# STM32L4Q5xx register map
File version: 1.0
Registers are 32-bit, read-write, reset 0x0 unless marked. A register's access mark holds for its fields unless they carry their own. Offsets are from the block's base; [hi:lo] are bit positions; {n}, {i} and the like mark numbered series.

## PWR — Power Control
Base 0x40007000
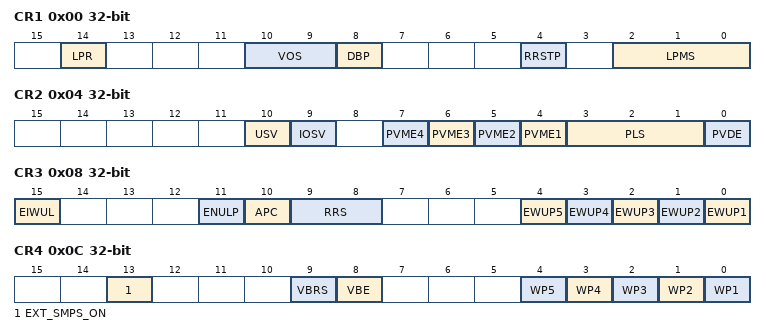
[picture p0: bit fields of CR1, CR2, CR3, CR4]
0x00 CR1 — PWR power control register 1
  [14] LPR — Regulator low-power mode
  [10:9] VOS — VOS[1:0] bits (Regulator voltage scaling output selection)
    1=SCALE1; 2=SCALE2
  [8] DBP — Disable Back-up domain Protection
  [4] RRSTP — SRAM3 Retention in Stop 2 mode
  [2:0] LPMS — Low-power mode selection field
    0=STOP0; 1=STOP1; 2=STOP2; 3=STANDBY; 4=SHUTDOWN
0x04 CR2 — PWR power control register 2
  [10] USV — VDD USB Supply Valid
  [9] IOSV — VDD IO2 independent I/Os Supply Valid
  [n+3] PVME{n} (n=1..4) — PVM {n} Enable
  [3:1] PLS — PVD level selection
    {v}=PVDLEVEL_{v} (v=0..7)
  [0] PVDE — Power Voltage Detector Enable
0x08 CR3 — PWR power control register 3
  [15] EIWUL — Enable Internal Wake-up line
  [11] ENULP — Enable ULP BORL, BORH and PVD for STOP2 and Standby modes
  [10] APC — Apply pull-up and pull-down configuration
  [9:8] RRS
    0=NO_SRAM2_RETENTION; 1=FULL_SRAM2_RETENTION; 2=PWR_4KBYTES_SRAM2_RETENTION
  [n-1] EWUP{n} (n=1..5) — Enable Wake-Up Pin {n}
0x0C CR4 — PWR power control register 4
  [13] EXT_SMPS_ON — Inform the internal regulator on external SMPS switch status
  [9] VBRS — VBAT Battery charging Resistor Selection
    0=CHARG_RESISTOR_5K; 1=CHARGRESISTOR_1_5K
  [8] VBE — VBAT Battery charging Enable
  [n-1] WP{n} (n=1..5) — Wake-Up Pin {n} polarity
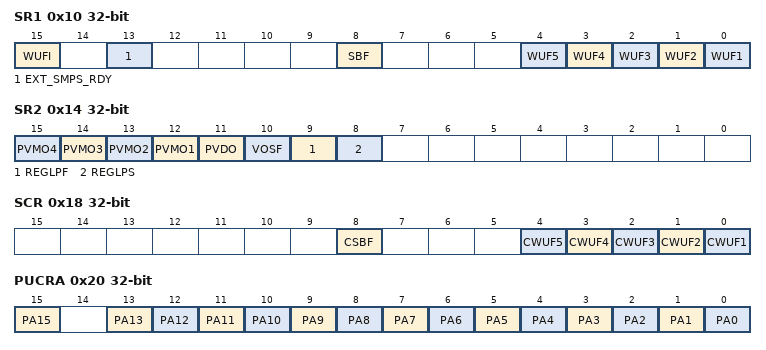
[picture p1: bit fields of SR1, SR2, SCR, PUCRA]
0x10 SR1 — PWR power status register 1
  [15] WUFI — Wake-Up Flag Internal
  [13] EXT_SMPS_RDY — Switching to external SMPS Ready Flag
  [8] SBF — Stand-By Flag
  [n-1] WUF{n} (n=1..5) — Wake-up Flag {n}
0x14 SR2 — PWR power status register 2
  [n+11] PVMO{n} (n=1..4) — Peripheral Voltage Monitoring Output {n}
  [11] PVDO — Power Voltage Detector Output
  [10] VOSF — Voltage Scaling Flag
  [9] REGLPF — Low-power Regulator Flag
  [8] REGLPS — Low-power Regulator Started
0x18 SCR — PWR power status reset register
  [8] CSBF — Clear Stand-By Flag
  [n-1] CWUF{n} (n=1..5) — Clear Wake-up Flag {n}
0x20 PUCRA — Pull_up control register of portA
  [15] PA15 — Port PA15 Pull-Up set
  [n] PA{n} (n=0..13) — Port PA{n} Pull-Up set
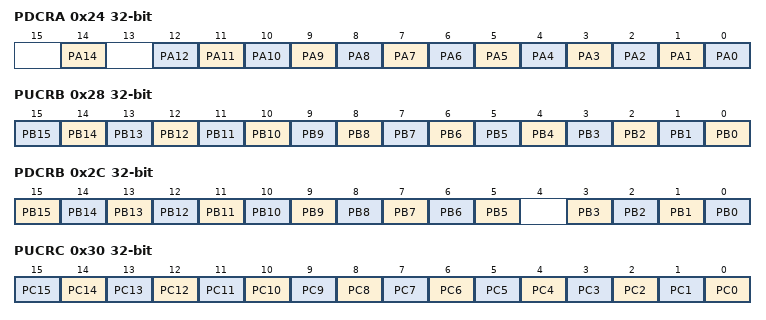
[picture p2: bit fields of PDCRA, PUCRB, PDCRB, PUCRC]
0x24 PDCRA — Pull_Down control register of portA
  [14] PA14 — Port PA14 Pull-Down set
  [n] PA{n} (n=0..12) — Port PA{n} Pull-Down set
0x28 PUCRB — Pull_up control register of portB
  [n] PB{n} (n=0..15) — Port PB{n} Pull-Up set
0x2C PDCRB — Pull_Down control register of portB
  [n] PB{n} (n=5..15) — Port PB{n} Pull-Down set
  [n] PB{n} (n=0..3) — Port PB{n} Pull-Down set
0x30 PUCRC — Pull_up control register of portC
  [n] PC{n} (n=0..15) — Port PC{n} Pull-Up set
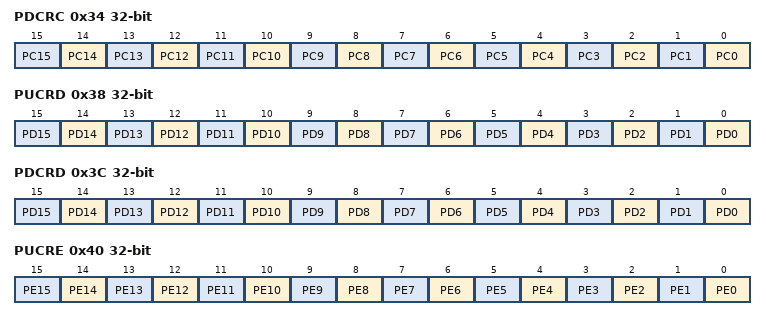
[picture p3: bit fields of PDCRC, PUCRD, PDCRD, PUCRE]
0x34 PDCRC — Pull_Down control register of portC
  [n] PC{n} (n=0..15) — Port PC{n} Pull-Down set
0x38 PUCRD — Pull_up control register of portD
  [n] PD{n} (n=0..15) — Port PD{n} Pull-Up set
0x3C PDCRD — Pull_Down control register of portD
  [n] PD{n} (n=0..15) — Port PD{n} Pull-Down set
0x40 PUCRE — Pull_up control register of portE
  [n] PE{n} (n=0..15) — Port PE{n} Pull-Up set
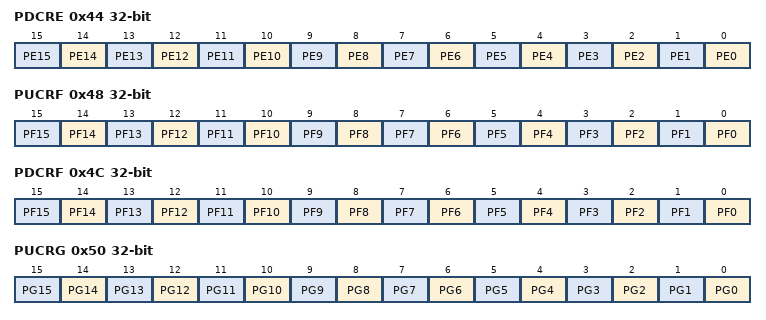
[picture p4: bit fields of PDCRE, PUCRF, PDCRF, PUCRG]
0x44 PDCRE — Pull_Down control register of portE
  [n] PE{n} (n=0..15) — Port PE{n} Pull-Down set
0x48 PUCRF — Pull_up control register of portF
  [n] PF{n} (n=0..15) — Port PF{n} Pull-Up set
0x4C PDCRF — Pull_Down control register of portF
  [n] PF{n} (n=0..15) — Port PF{n} Pull-Down set
0x50 PUCRG — Pull_up control register of portG
  [n] PG{n} (n=0..15) — Port PG{n} Pull-Up set
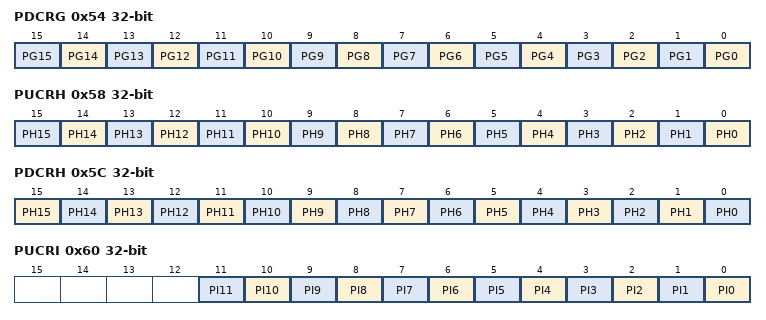
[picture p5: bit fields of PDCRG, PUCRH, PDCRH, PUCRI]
0x54 PDCRG — Pull_Down control register of portG
  [n] PG{n} (n=0..15) — Port PG{n} Pull-Down set
0x58 PUCRH — Pull_up control register of portH
  [n] PH{n} (n=0..15) — Port PH{n} Pull-Up set
0x5C PDCRH — Pull_Down control register of portH
  [n] PH{n} (n=3..15) — Port PH{n} Pull-Down set
  [2] PH2 — Port PH1 Pull-Down set
  [1] PH1 — Port PH1 Pull-Down set
  [0] PH0 — Port PH0 Pull-Down set
0x60 PUCRI — Pull_up control register of portI
  [n] PI{n} (n=0..11) — Port PI{n} Pull-Up set
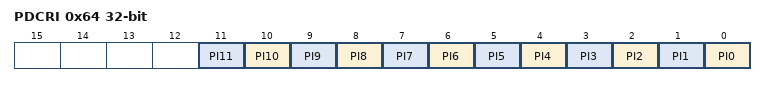
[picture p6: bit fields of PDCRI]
0x64 PDCRI — Pull_Down control register of portI
  [n] PI{n} (n=0..11) — Port PI{n} Pull-Down set
0x80 CR5 — PWR power control register 5
  [8] R1MODE — Range 1 normal mode
